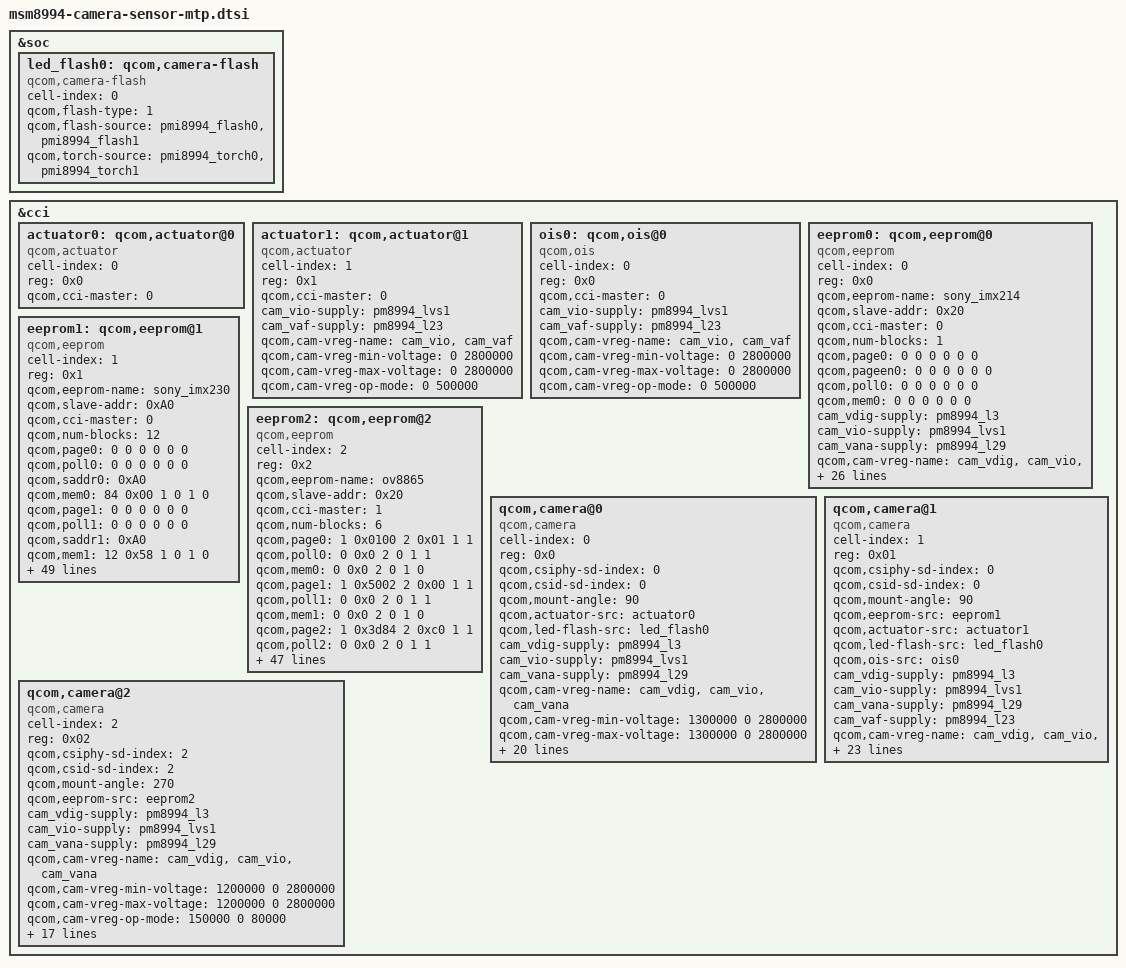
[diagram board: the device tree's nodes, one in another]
/*
 * Copyright (c) 2014, The Linux Foundation. All rights reserved.
 *
 * This program is free software; you can redistribute it and/or modify
 * it under the terms of the GNU General Public License version 2 and
 * only version 2 as published by the Free Software Foundation.
 *
 * This program is distributed in the hope that it will be useful,
 * but WITHOUT ANY WARRANTY; without even the implied warranty of
 * MERCHANTABILITY or FITNESS FOR A PARTICULAR PURPOSE.  See the
 * GNU General Public License for more details.
 */

&soc {	
  led_flash0: qcom,camera-flash {
       cell-index = <0>;	 
       compatible = "qcom,camera-flash";	 
       qcom,flash-type = <1>;	 
       qcom,flash-source = <&pmi8994_flash0 &pmi8994_flash1>;	 
       qcom,torch-source = <&pmi8994_torch0 &pmi8994_torch1>;	 
    };	 
};


&cci {
	actuator0: qcom,actuator@0 {
		cell-index = <0>;
		reg = <0x0>;
		compatible = "qcom,actuator";
		qcom,cci-master = <0>;
	};
	
	actuator1: qcom,actuator@1 {
		cell-index = <1>;
		reg = <0x1>;
		compatible = "qcom,actuator";
		qcom,cci-master = <0>;
		cam_vio-supply = <&pm8994_lvs1>;
		cam_vaf-supply = <&pm8994_l23>;
		qcom,cam-vreg-name = "cam_vio", "cam_vaf";
		qcom,cam-vreg-min-voltage = <0 2800000>;
		qcom,cam-vreg-max-voltage = <0 2800000>;
		qcom,cam-vreg-op-mode = <0 500000>;
	};

	ois0: qcom,ois@0 {
		cell-index = <0>;
		reg = <0x0>;
		compatible = "qcom,ois";
		qcom,cci-master = <0>;
		cam_vio-supply = <&pm8994_lvs1>;
		cam_vaf-supply = <&pm8994_l23>;
		qcom,cam-vreg-name = "cam_vio", "cam_vaf";
		qcom,cam-vreg-min-voltage = <0 2800000>;
		qcom,cam-vreg-max-voltage = <0 2800000>;
		qcom,cam-vreg-op-mode = <0 500000>;
	};

	eeprom0: qcom,eeprom@0 {
		cell-index = <0>;
		reg = <0x0>;
		qcom,eeprom-name = "sony_imx214";
		compatible = "qcom,eeprom";
		qcom,slave-addr = <0x20>;
		qcom,cci-master = <0>;
		qcom,num-blocks = <1>;
		qcom,page0 = <0 0 0 0 0 0>;
		qcom,pageen0 = <0 0 0 0 0 0>;
		qcom,poll0 = <0 0 0 0 0 0>;
		qcom,mem0 = <0 0 0 0 0 0>;
		cam_vdig-supply = <&pm8994_l3>;
		cam_vio-supply = <&pm8994_lvs1>;
		cam_vana-supply = <&pm8994_l29>;
		qcom,cam-vreg-name = "cam_vdig", "cam_vio", "cam_vana";
		qcom,cam-vreg-min-voltage = <1200000 0 2700000>;
		qcom,cam-vreg-max-voltage = <1200000 0 2700000>;
		qcom,cam-vreg-op-mode = <150000 0 200000>;
		
		qcom,gpio-no-mux = <0>;
		pinctrl-names = "cam_default", "cam_suspend";
		pinctrl-0 = <&cam_sensor_mclk0_active &cam_sensor_rear_active>;
		pinctrl-1 = <&cam_sensor_mclk0_suspend &cam_sensor_rear_suspend>;
		gpios = <&msm_gpio 13 0>,
			<&msm_gpio 92 0>,
			<&msm_gpio 114 0>;
		qcom,gpio-reset = <1>;
		qcom,gpio-standby = <2>;
		qcom,gpio-req-tbl-num = <0 1 2>;
		qcom,gpio-req-tbl-flags = <1 0 0>;
		qcom,gpio-req-tbl-label = "CAMIF_MCLK0",
					  "CAM_RESET0",
					  "CAM_STANDBY0";
		qcom,cam-power-seq-type = "sensor_vreg", "sensor_vreg", "sensor_vreg",
			"sensor_gpio", "sensor_gpio" , "sensor_clk";
		qcom,cam-power-seq-val = "cam_vdig", "cam_vana", "cam_vio",
			"sensor_gpio_reset", "sensor_gpio_standby","sensor_cam_mclk";
		qcom,cam-power-seq-cfg-val = <1 1 1 1 1 24000000>;
		qcom,cam-power-seq-delay = <1 1 1 30 30 5>;
		status = "ok";
		clocks = <&clock_mmss clk_mclk0_clk_src>,
				<&clock_mmss clk_camss_mclk0_clk>;
		clock-names = "cam_src_clk", "cam_clk";
	};

	eeprom1: qcom,eeprom@1 {
		cell-index = <1>;
		reg = <0x1>;
		qcom,eeprom-name = "sony_imx230";
		compatible = "qcom,eeprom";
		qcom,slave-addr = <0xA0>;
		qcom,cci-master = <0>;
		qcom,num-blocks = <12>;
		
		qcom,page0 = <0 0 0 0 0 0>;
		qcom,poll0 = <0 0 0 0 0 0>;
		qcom,saddr0 = <0xA0>;
		qcom,mem0 = <84 0x00 1 0 1 0>;
		
		qcom,page1 = <0 0 0 0 0 0>;
		qcom,poll1 = <0 0 0 0 0 0>;
		qcom,saddr1 = <0xA0>;
		qcom,mem1 = <12 0x58 1 0 1 0>;
		
		qcom,page2 = <0 0 0 0 0 0>;
		qcom,poll2 = <0 0 0 0 0 0>;
		qcom,saddr2 = <0xA0>;
		qcom,mem2 = <12 0x70 1 0 1 0>;
		
		qcom,page3 = <0 0 0 0 0 0>;
		qcom,poll3 = <0 0 0 0 0 0>;
		qcom,saddr3 = <0xA0>;
		qcom,mem3 = <112 0x90 1 0 1 0>;
		
		qcom,page4 = <0 0 0 0 0 0>;
		qcom,poll4 = <0 0 0 0 0 0>;
		qcom,saddr4 = <0xA2>;
		qcom,mem4 = <256 0x00 1 0 1 0>;
		
		qcom,page5 = <0 0 0 0 0 0>;
		qcom,poll5 = <0 0 0 0 0 0>;
		qcom,saddr5 = <0xA4>;
		qcom,mem5 = <256 0x00 1 0 1 0>;
		
		qcom,page6 = <0 0 0 0 0 0>;
		qcom,poll6 = <0 0 0 0 0 0>;
		qcom,saddr6 = <0xA6>;
		qcom,mem6 = <256 0x00 1 0 1 0>;
		
		qcom,page7 = <0 0 0 0 0 0>;
		qcom,poll7 = <0 0 0 0 0 0>;
		qcom,saddr7 = <0xA8>;
		qcom,mem7 = <256 0x00 1 0 1 0>;
		
		qcom,page8 = <0 0 0 0 0 0>;
		qcom,poll8 = <0 0 0 0 0 0>;
		qcom,saddr8 = <0xAA>;
		qcom,mem8 = <256 0x00 1 0 1 0>;
		
		qcom,page9 = <0 0 0 0 0 0>;
		qcom,poll9 = <0 0 0 0 0 0>;
		qcom,saddr9 = <0xAC>;
		qcom,mem9 = <256 0x00 1 0 1 0>;
		
		qcom,page10 = <0 0 0 0 0 0>;
		qcom,poll10 = <0 0 0 0 0 0>;
		qcom,saddr10 = <0xAE>;
		qcom,mem10 = <122 0x00 1 0 1 0>;
		
		qcom,page11 = <0 0 0 0 0 0>;
		qcom,poll11 = <0 0 0 0 0 0>;
		qcom,saddr11 = <0xAE>;
		qcom,mem11 = <44 0xc0 1 0 1 0>;

		cam_vio-supply = <&pm8994_lvs1>;
		qcom,cam-vreg-name = "cam_vio";
		qcom,cam-vreg-min-voltage = <0>;
		qcom,cam-vreg-max-voltage = <0>;
		qcom,cam-vreg-op-mode = <0>;
		qcom,cam-power-seq-type = "sensor_vreg";
		qcom,cam-power-seq-val = "cam_vio";
		qcom,cam-power-seq-cfg-val = <1>;
		qcom,cam-power-seq-delay = <1>;
		status = "ok";
	};

	eeprom2: qcom,eeprom@2 {
		cell-index = <2>;
		reg = <0x2>;
		qcom,eeprom-name = "ov8865";
		compatible = "qcom,eeprom";
		qcom,slave-addr = <0x20>;
		qcom,cci-master = <1>;
		qcom,num-blocks = <6>;
		
		qcom,page0 = <1 0x0100 2 0x01 1 1>;
		qcom,poll0 = <0 0x0 2 0 1 1>;
		qcom,mem0 = <0 0x0 2 0 1 0>;
		
		qcom,page1 = <1 0x5002 2 0x00 1 1>;
		qcom,poll1 = <0 0x0 2 0 1 1>;
		qcom,mem1 = <0 0x0 2 0 1 0>;

		qcom,page2 = <1 0x3d84 2 0xc0 1 1>;
		qcom,poll2 = <0 0x0 2 0 1 1>;
		qcom,mem2 = <0 0x0 2 0 1 0>;

		qcom,page3 = <1 0x3d88 2 0x7010 2 1>;
		qcom,poll3 = <0 0x0 2 0 1 1>;
		qcom,mem3 = <0 0x0 2 0 1 0>;

		qcom,page4 = <1 0x3d8a 2 0x7100 2 1>;
		qcom,pageen4 = <1 0x3d81 2 0x01 1 10>;
		qcom,poll4 = <0 0x0 2 0 1 0>;
		qcom,mem4 = <241 0x7010 2 0 1 1>;
		
		qcom,page5 = <1 0x5002 2 0x08 1 1>;
		qcom,poll5 = <0 0x0 2 0 1 1>;
		qcom,mem5 = <0 0x0 2 0 1 0>;

		cam_vdig-supply = <&pm8994_l3>;
		cam_vio-supply = <&pm8994_lvs1>;
		cam_vana-supply = <&pm8994_l29>;
		qcom,cam-vreg-name = "cam_vdig", "cam_vio", "cam_vana";
		qcom,cam-vreg-min-voltage = <1200000 0 2800000>;
		qcom,cam-vreg-max-voltage = <1200000 0 2800000>;
		qcom,cam-vreg-op-mode = <105000 0 80000>;
		qcom,gpio-no-mux = <0>;
		pinctrl-names = "cam_default", "cam_suspend";
		pinctrl-0 = <&cam_sensor_mclk2_active &cam_sensor_front_active>;
		pinctrl-1 = <&cam_sensor_mclk2_suspend &cam_sensor_front_suspend>;
		gpios = <&msm_gpio 15 0>,
			<&msm_gpio 104 0>,
			<&msm_gpio 105 0>;
		qcom,gpio-reset = <1>;
		qcom,gpio-standby = <2>;
		qcom,gpio-req-tbl-num = <0 1 2>;
		qcom,gpio-req-tbl-flags = <1 0 0>;
		qcom,gpio-req-tbl-label = "CAMIF_MCLK2",
					  "CAM_RESET2",
					  "CAM_STANDBY2";
		qcom,gpio-set-tbl-num = <1 1 2 2>;
		qcom,gpio-set-tbl-flags = <0 2 0 2>;
		qcom,gpio-set-tbl-delay = <1000 5000 10000 10000>;
		qcom,cam-power-seq-type = "sensor_gpio", "sensor_vreg", "sensor_gpio" , "sensor_vreg", "sensor_vreg",
			"sensor_gpio", "sensor_gpio" , "sensor_clk";
		qcom,cam-power-seq-val =  "sensor_gpio_standby", "cam_vio", "sensor_gpio_standby", "cam_vana", "cam_vdig", "sensor_gpio_reset",
			"sensor_gpio_reset", "sensor_cam_mclk";
		qcom,cam-power-seq-cfg-val = <0 1 1 1 1 0 1 24000000>;
		qcom,cam-power-seq-delay = <1 1 5 1 1 10 10 10>;
		status = "ok";
		clocks = <&clock_mmss clk_mclk2_clk_src>,
				<&clock_mmss clk_camss_mclk2_clk>;
		clock-names = "cam_src_clk", "cam_clk";
	};

	qcom,camera@0 {
		cell-index = <0>;
		compatible = "qcom,camera";
		reg = <0x0>;
		qcom,csiphy-sd-index = <0>;
		qcom,csid-sd-index = <0>;
		qcom,mount-angle = <90>;
		qcom,actuator-src = <&actuator0>;
		qcom,led-flash-src = <&led_flash0>;
		cam_vdig-supply = <&pm8994_l3>;
		cam_vio-supply = <&pm8994_lvs1>;
		cam_vana-supply = <&pm8994_l29>;
		qcom,cam-vreg-name = "cam_vdig", "cam_vio", "cam_vana";
		qcom,cam-vreg-min-voltage = <1300000 0 2800000>;
		qcom,cam-vreg-max-voltage = <1300000 0 2800000>;
		qcom,cam-vreg-op-mode = <500000 0 300000>;

		qcom,gpio-no-mux = <0>;
		pinctrl-names = "cam_default", "cam_suspend";
		pinctrl-0 = <&cam_sensor_mclk0_active &cam_sensor_rear_active>;
		pinctrl-1 = <&cam_sensor_mclk0_suspend &cam_sensor_rear_suspend>;
		gpios = <&msm_gpio 13 0>,			
			<&msm_gpio 92 0>,
			<&msm_gpio 114 0>,
			<&msm_gpio 33 0>;
		qcom,gpio-reset = <1>;
		qcom,gpio-standby = <2>;// not used
		qcom,gpio-vaf = <3>;// slave sel
		qcom,gpio-req-tbl-num = <0 1 2 3>;
		qcom,gpio-req-tbl-flags = <1 0 0 0>;
		qcom,gpio-req-tbl-label = "CAMIF_MCLK0",
					  "CAM_RESET0",
					  "CAM_STANDBY0",
					  "CAM_VAF0";
		qcom,sensor-position = <0>;
		qcom,sensor-mode = <0>;
		qcom,cci-master = <0>;
		status = "ok";
		clocks = <&clock_mmss clk_mclk0_clk_src>,
				<&clock_mmss clk_camss_mclk0_clk>;
		clock-names = "cam_src_clk", "cam_clk";
	};

		qcom,camera@1 {
		cell-index = <1>;
		compatible = "qcom,camera";
		reg = <0x01>;
		qcom,csiphy-sd-index = <0>;
		qcom,csid-sd-index = <0>;
		qcom,mount-angle = <90>;
		qcom,eeprom-src = <&eeprom1>;
		qcom,actuator-src = <&actuator1>;
		qcom,led-flash-src = <&led_flash0>;
		qcom,ois-src = <&ois0>;
		cam_vdig-supply = <&pm8994_l3>;
		cam_vio-supply = <&pm8994_lvs1>;
		cam_vana-supply = <&pm8994_l29>;
		cam_vaf-supply = <&pm8994_l23>;
		qcom,cam-vreg-name = "cam_vdig", "cam_vio", "cam_vana", "cam_vaf";
		qcom,cam-vreg-min-voltage = <1100000 0 2600000 2800000>;
		qcom,cam-vreg-max-voltage = <1100000 0 2600000 2800000>;
		qcom,cam-vreg-op-mode = <105000 0 80000 500000>;

		qcom,gpio-no-mux = <0>;
		pinctrl-names = "cam_default", "cam_suspend";
		pinctrl-0 = <&cam_sensor_mclk0_active &cam_sensor_rear_active>;
		pinctrl-1 = <&cam_sensor_mclk0_suspend &cam_sensor_rear_suspend>;
		gpios = <&msm_gpio 13 0>,			
			<&msm_gpio 92 0>,
			<&msm_gpio 114 0>;
		qcom,gpio-reset = <1>;
		qcom,gpio-standby = <2>;
		qcom,gpio-req-tbl-num = <0 1 2>;
		qcom,gpio-req-tbl-flags = <1 0 0>;
		qcom,gpio-req-tbl-label = "CAMIF_MCLK1",
					  "CAM_RESET1",
					  "CAM_STANDBY1";
		qcom,sensor-position = <0>;
		qcom,sensor-mode = <0>;
		qcom,cci-master = <0>;
		status = "ok";
		clocks = <&clock_mmss clk_mclk0_clk_src>,
			<&clock_mmss clk_camss_mclk0_clk>;
		clock-names = "cam_src_clk", "cam_clk";
	};

	qcom,camera@2 {
		cell-index = <2>;
		compatible = "qcom,camera";
		reg = <0x02>;
		qcom,csiphy-sd-index = <2>;
		qcom,csid-sd-index = <2>;
		qcom,mount-angle = <270>;
		qcom,eeprom-src = <&eeprom2>;
		cam_vdig-supply = <&pm8994_l3>;
		cam_vio-supply = <&pm8994_lvs1>;
		cam_vana-supply = <&pm8994_l29>;
		qcom,cam-vreg-name = "cam_vdig", "cam_vio", "cam_vana";
		qcom,cam-vreg-min-voltage = <1200000 0 2800000>;
		qcom,cam-vreg-max-voltage = <1200000 0 2800000>;
		qcom,cam-vreg-op-mode = <150000 0 80000>;
		qcom,gpio-no-mux = <0>;
		pinctrl-names = "cam_default", "cam_suspend";
		pinctrl-0 = <&cam_sensor_mclk2_active &cam_sensor_front_active>;
		pinctrl-1 = <&cam_sensor_mclk2_suspend &cam_sensor_front_suspend>;
		gpios = <&msm_gpio 15 0>,
			<&msm_gpio 104 0>,
			<&msm_gpio 105 0>;
		qcom,gpio-reset = <1>;
		qcom,gpio-standby = <2>; // slave sel
		qcom,gpio-req-tbl-num = <0 1 2>;
		qcom,gpio-req-tbl-flags = <1 0 0>;
		qcom,gpio-req-tbl-label = "CAMIF_MCLK2",
					  "CAM_RESET2",
					  "CAM_STANDBY2";
		qcom,sensor-position = <1>;
		qcom,sensor-mode = <0>;
		qcom,cci-master = <1>;
		status = "ok";
		clocks = <&clock_mmss clk_mclk2_clk_src>,
			<&clock_mmss clk_camss_mclk2_clk>;
		clock-names = "cam_src_clk", "cam_clk";
	};
};
